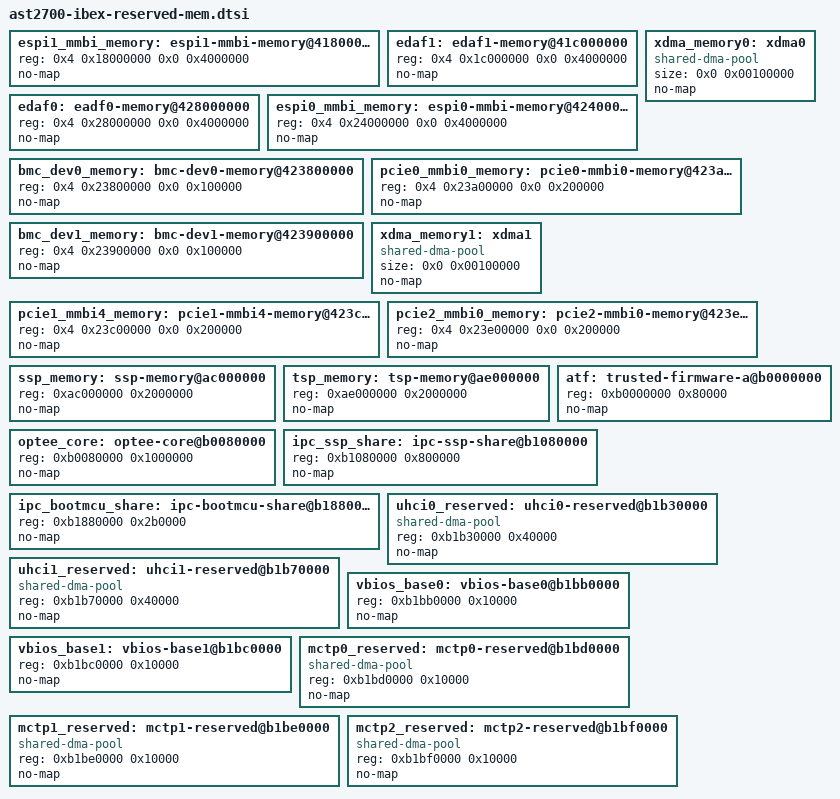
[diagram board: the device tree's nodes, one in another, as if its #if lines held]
// SPDX-License-Identifier: GPL-2.0-or-later

/* AST2700 reserved memories with no-map property */

#if DUAL_NODE
espi1_mmbi_memory: espi1-mmbi-memory@418000000 {
	reg = <0x4 0x18000000 0x0 0x4000000>;
	no-map;
	bootph-all;
};

edaf1: edaf1-memory@41c000000 {
	reg = <0x4 0x1c000000 0x0 0x4000000>;
	no-map;
	bootph-all;
};
#endif

edaf0: eadf0-memory@428000000 {
	reg = <0x4 0x28000000 0x0 0x4000000>;
	no-map;
	bootph-all;
};

espi0_mmbi_memory: espi0-mmbi-memory@424000000 {
	reg = <0x4 0x24000000 0x0 0x4000000>;
	no-map;
	bootph-all;
};

#if PCIE0_EP
bmc_dev0_memory: bmc-dev0-memory@423800000 {
	reg = <0x4 0x23800000 0x0 0x100000>;
	no-map;
	bootph-all;
};

xdma_memory0: xdma0 {
	size = <0x0 0x00100000>;
	compatible = "shared-dma-pool";
	no-map;
	bootph-all;
};

pcie0_mmbi0_memory: pcie0-mmbi0-memory@423a00000 {
	reg = <0x4 0x23a00000 0x0 0x200000>;
	no-map;
	bootph-all;
};
#endif

#if PCIE1_EP
bmc_dev1_memory: bmc-dev1-memory@423900000 {
	reg = <0x4 0x23900000 0x0 0x100000>;
	no-map;
	bootph-all;
};

xdma_memory1: xdma1 {
	size = <0x0 0x00100000>;
	compatible = "shared-dma-pool";
	no-map;
	bootph-all;
};

pcie1_mmbi4_memory: pcie1-mmbi4-memory@423c00000 {
	reg = <0x4 0x23c00000 0x0 0x200000>;
	no-map;
	bootph-all;
};
#endif

pcie2_mmbi0_memory: pcie2-mmbi0-memory@423e00000 {
	reg = <0x4 0x23e00000 0x0 0x200000>;
	no-map;
	bootph-all;
};

ssp_memory: ssp-memory@ac000000 {
	reg = <0xac000000 0x2000000>;
	no-map;
	bootph-all;
};

tsp_memory: tsp-memory@ae000000 {
	reg = <0xae000000 0x2000000>;
	no-map;
	bootph-all;
};

atf: trusted-firmware-a@b0000000 {
	reg = <0xb0000000 0x80000>;
	no-map;
	bootph-all;
};

optee_core: optee-core@b0080000 {
	reg = <0xb0080000 0x1000000>;
	no-map;
	bootph-all;
};

ipc_ssp_share: ipc-ssp-share@b1080000 {
	reg = <0xb1080000 0x800000>;
	no-map;
	bootph-all;
};

ipc_bootmcu_share: ipc-bootmcu-share@b1880000 {
	reg = <0xb1880000 0x2b0000>;
	no-map;
};

uhci0_reserved: uhci0-reserved@b1b30000 {
	reg = <0xb1b30000 0x40000>;
	compatible = "shared-dma-pool";
	no-map;
	bootph-all;
};

uhci1_reserved: uhci1-reserved@b1b70000 {
	reg = <0xb1b70000 0x40000>;
	compatible = "shared-dma-pool";
	no-map;
	bootph-all;
};

vbios_base0: vbios-base0@b1bb0000 {
	reg = <0xb1bb0000 0x10000>;
	no-map;
	bootph-all;
};

vbios_base1: vbios-base1@b1bc0000 {
	reg = <0xb1bc0000 0x10000>;
	no-map;
	bootph-all;
};

mctp0_reserved: mctp0-reserved@b1bd0000 {
	reg = <0xb1bd0000 0x10000>;
	compatible = "shared-dma-pool";
	no-map;
	bootph-all;
};

mctp1_reserved: mctp1-reserved@b1be0000 {
	reg = <0xb1be0000 0x10000>;
	compatible = "shared-dma-pool";
	no-map;
	bootph-all;
};

mctp2_reserved: mctp2-reserved@b1bf0000 {
	reg = <0xb1bf0000 0x10000>;
	compatible = "shared-dma-pool";
	no-map;
	bootph-all;
};
